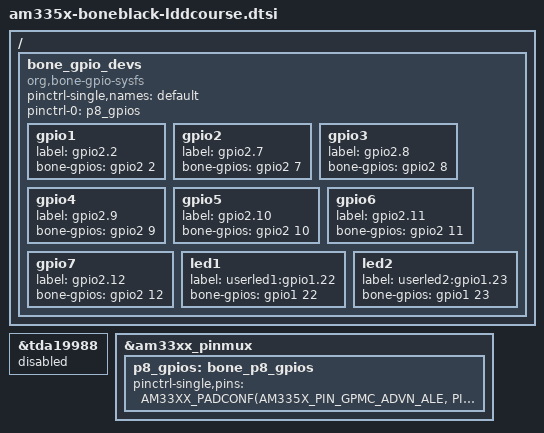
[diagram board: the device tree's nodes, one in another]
// This file would then be added as an include in am335x-boneblack.dts
// make ARCH=arm CROSS_COMPILE=arm-linux-gnueabihf- am335x-boneblack.dtb

/ {
  bone_gpio_devs {
    compatible = "org,bone-gpio-sysfs";
    pinctrl-single,names = "default";
    pinctrl-0 = <&p8_gpios>;

    gpio1 {
      label = "gpio2.2";
      bone-gpios = <&gpio2 2 GPIO_ACTIVE_HIGH>;
    };
    gpio2 {
      label = "gpio2.7";
      bone-gpios = <&gpio2 7 GPIO_ACTIVE_HIGH>;
    };
    gpio3 {
      label = "gpio2.8";
      bone-gpios = <&gpio2 8 GPIO_ACTIVE_HIGH>;
    };
    gpio4 {
      label = "gpio2.9";
      bone-gpios = <&gpio2 9 GPIO_ACTIVE_HIGH>;
    };
    gpio5 {
      label = "gpio2.10";
      bone-gpios = <&gpio2 10 GPIO_ACTIVE_HIGH>;
    };
    gpio6 {
      label = "gpio2.11";
      bone-gpios = <&gpio2 11 GPIO_ACTIVE_HIGH>;
    };
    gpio7 {
      label = "gpio2.12";
      bone-gpios = <&gpio2 12 GPIO_ACTIVE_HIGH>;
    };
    led1 {
      label = "userled1:gpio1.22";
      bone-gpios = <&gpio1 22 GPIO_ACTIVE_HIGH>;
    };
    led2 {
      label = "userled2:gpio1.23";
      bone-gpios = <&gpio1 23 GPIO_ACTIVE_HIGH>;
    };
  };
};

// Disable HDMI node using the same pins as p8_gpios below. Can not use both, so if
// you were using the HDMI node, you would have to pick different pins for p8_gpios.
&tda19988 {
  status = "disabled";
};

&am33xx_pinmux {
  p8_gpios: bone_p8_gpios {
    pinctrl-single,pins = <
      AM33XX_PADCONF(AM335X_PIN_GPMC_ADVN_ALE, PIN_OUTPUT, MUX_MODE7)
      AM33XX_PADCONF(AM335X_PIN_LCD_DATA1, PIN_OUTPUT, MUX_MODE7)
      AM33XX_PADCONF(AM335X_PIN_LCD_DATA2, PIN_OUTPUT, MUX_MODE7)
      AM33XX_PADCONF(AM335X_PIN_LCD_DATA3, PIN_OUTPUT, MUX_MODE7)
      AM33XX_PADCONF(AM335X_PIN_LCD_DATA4, PIN_OUTPUT, MUX_MODE7)
      AM33XX_PADCONF(AM335X_PIN_LCD_DATA5, PIN_OUTPUT, MUX_MODE7)
      AM33XX_PADCONF(AM335X_PIN_LCD_DATA6, PIN_OUTPUT, MUX_MODE7)
    >;
  };
};
